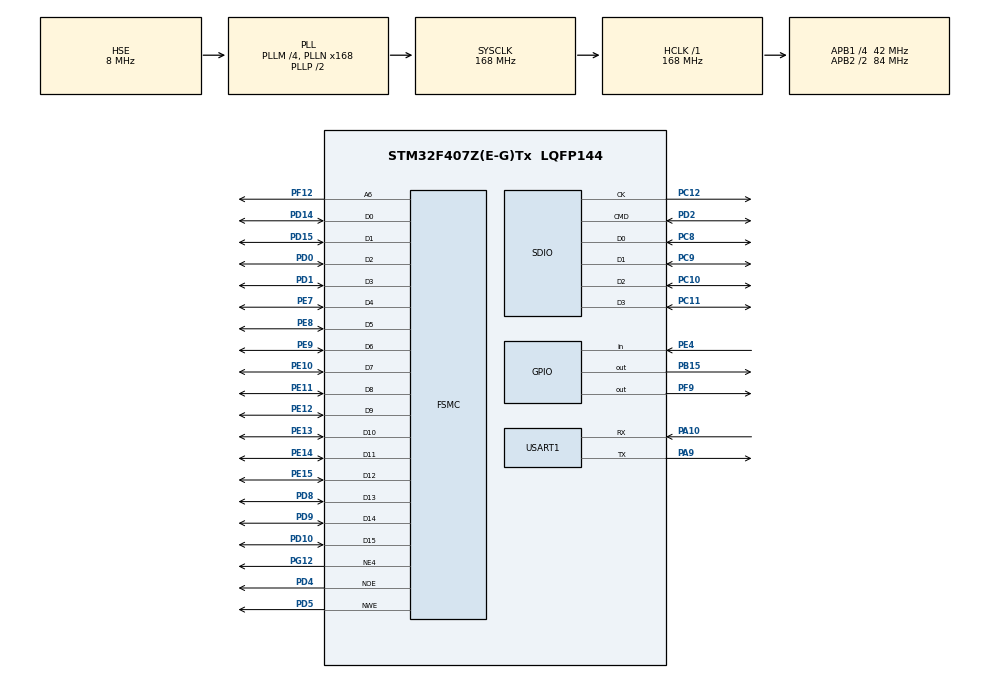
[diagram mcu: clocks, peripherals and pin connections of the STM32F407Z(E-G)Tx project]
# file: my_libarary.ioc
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Dma.Request0=USART1_RX
Dma.Request1=USART1_TX
Dma.Request2=SDIO
Dma.SDIO.2.Direction=DMA_PERIPH_TO_MEMORY
Dma.SDIO.2.FIFOMode=DMA_FIFOMODE_ENABLE
Dma.SDIO.2.FIFOThreshold=DMA_FIFO_THRESHOLD_FULL
Dma.SDIO.2.Instance=DMA2_Stream3
Dma.SDIO.2.MemBurst=DMA_MBURST_INC4
Dma.SDIO.2.MemDataAlignment=DMA_MDATAALIGN_WORD
Dma.SDIO.2.MemInc=DMA_MINC_ENABLE
Dma.SDIO.2.Mode=DMA_PFCTRL
Dma.SDIO.2.PeriphBurst=DMA_PBURST_INC4
Dma.SDIO.2.PeriphDataAlignment=DMA_PDATAALIGN_WORD
Dma.SDIO.2.PeriphInc=DMA_PINC_DISABLE
Dma.SDIO.2.Priority=DMA_PRIORITY_LOW
Dma.USART1_RX.0.Direction=DMA_PERIPH_TO_MEMORY
Dma.USART1_RX.0.FIFOMode=DMA_FIFOMODE_DISABLE
Dma.USART1_RX.0.Instance=DMA2_Stream2
Dma.USART1_RX.0.MemDataAlignment=DMA_MDATAALIGN_BYTE
Dma.USART1_RX.0.MemInc=DMA_MINC_ENABLE
Dma.USART1_RX.0.Mode=DMA_CIRCULAR
Dma.USART1_RX.0.PeriphDataAlignment=DMA_PDATAALIGN_BYTE
Dma.USART1_RX.0.PeriphInc=DMA_PINC_DISABLE
Dma.USART1_RX.0.Priority=DMA_PRIORITY_LOW
Dma.USART1_TX.1.Direction=DMA_MEMORY_TO_PERIPH
Dma.USART1_TX.1.FIFOMode=DMA_FIFOMODE_DISABLE
Dma.USART1_TX.1.Instance=DMA2_Stream7
Dma.USART1_TX.1.MemDataAlignment=DMA_MDATAALIGN_BYTE
Dma.USART1_TX.1.MemInc=DMA_MINC_ENABLE
Dma.USART1_TX.1.Mode=DMA_NORMAL
Dma.USART1_TX.1.PeriphDataAlignment=DMA_PDATAALIGN_BYTE
Dma.USART1_TX.1.PeriphInc=DMA_PINC_DISABLE
Dma.USART1_TX.1.Priority=DMA_PRIORITY_LOW
FATFS.BSP.number=1
FATFS.USE_DMA_CODE_SD=1
FATFS._CODE_PAGE=936
FATFS._USE_LFN=3
FATFS0.BSP.STBoard=false
FATFS0.BSP.api=Unknown
FATFS0.BSP.instance=PE4
FATFS0.BSP.ip=GPIO
FATFS0.BSP.mode=Input
FATFS0.BSP.name=Detect_SDIO
FATFS0.BSP.solution=PE4
Mcu.Family=STM32F4
Mcu.Name=STM32F407Z(E-G)Tx
Mcu.Package=LQFP144
NVIC.DMA2_Stream2_IRQn=true\:0\:0\:false\:false\:true\:false\:true\:true
NVIC.DMA2_Stream3_IRQn=true\:0\:0\:false\:false\:true\:false\:true\:true
NVIC.DMA2_Stream7_IRQn=true\:0\:0\:false\:false\:true\:false\:true\:true
NVIC.PriorityGroup=NVIC_PRIORITYGROUP_4
NVIC.SDIO_IRQn=true\:0\:0\:false\:false\:true\:true\:true\:true
NVIC.TIM6_DAC_IRQn=true\:0\:0\:false\:false\:true\:true\:true\:true
NVIC.TIM7_IRQn=true\:0\:0\:false\:false\:true\:true\:true\:true
NVIC.USART1_IRQn=true\:0\:0\:false\:false\:true\:true\:true\:true
PA10.Mode=Asynchronous
PA10.Signal=USART1_RX
PA13.Mode=Serial_Wire
PA13.Signal=SYS_JTMS-SWDIO
PA14.Mode=Serial_Wire
PA14.Signal=SYS_JTCK-SWCLK
PA9.Mode=Asynchronous
PA9.Signal=USART1_TX
PB15.Signal=GPIO_Output
PB3.Signal=SPI1_SCK
PB4.Signal=SPI1_MISO
PB5.Signal=SPI1_MOSI
PC10.Mode=SD_4_bits_Wide_bus
PC10.Signal=SDIO_D2
PC11.Mode=SD_4_bits_Wide_bus
PC11.Signal=SDIO_D3
PC12.Mode=SD_4_bits_Wide_bus
PC12.Signal=SDIO_CK
PC14-OSC32_IN.Mode=LSE-External-Oscillator
PC14-OSC32_IN.Signal=RCC_OSC32_IN
PC15-OSC32_OUT.Mode=LSE-External-Oscillator
PC15-OSC32_OUT.Signal=RCC_OSC32_OUT
PC8.Mode=SD_4_bits_Wide_bus
PC8.Signal=SDIO_D0
PC9.Mode=SD_4_bits_Wide_bus
PC9.Signal=SDIO_D1
PD0.Signal=FSMC_D2_DA2
PD1.Signal=FSMC_D3_DA3
PD10.Signal=FSMC_D15_DA15
PD14.Signal=FSMC_D0_DA0
PD15.Signal=FSMC_D1_DA1
PD2.Mode=SD_4_bits_Wide_bus
PD2.Signal=SDIO_CMD
PD4.Signal=FSMC_NOE
PD5.Signal=FSMC_NWE
PD8.Signal=FSMC_D13_DA13
PD9.Signal=FSMC_D14_DA14
PE10.Signal=FSMC_D7_DA7
PE11.Signal=FSMC_D8_DA8
PE12.Signal=FSMC_D9_DA9
PE13.Signal=FSMC_D10_DA10
PE14.Signal=FSMC_D11_DA11
PE15.Signal=FSMC_D12_DA12
PE4.Signal=GPIO_Input
PE7.Signal=FSMC_D4_DA4
PE8.Signal=FSMC_D5_DA5
PE9.Signal=FSMC_D6_DA6
PF12.Signal=FSMC_A6
PF9.Signal=GPIO_Output
PG12.Mode=NorPsramChipSelect4_1
PG12.Signal=FSMC_NE4
PH0-OSC_IN.Mode=HSE-External-Oscillator
PH0-OSC_IN.Signal=RCC_OSC_IN
PH1-OSC_OUT.Mode=HSE-External-Oscillator
PH1-OSC_OUT.Signal=RCC_OSC_OUT
ProjectManager.HeapSize=0x2000
ProjectManager.StackSize=0x2000
ProjectManager.TargetToolchain=STM32CubeIDE
RCC.48MHZClocksFreq_Value=48000000
RCC.AHBFreq_Value=168000000
RCC.APB1CLKDivider=RCC_HCLK_DIV4
RCC.APB1Freq_Value=42000000
RCC.APB1TimFreq_Value=84000000
RCC.APB2CLKDivider=RCC_HCLK_DIV2
RCC.APB2Freq_Value=84000000
RCC.APB2TimFreq_Value=168000000
RCC.CortexFreq_Value=168000000
RCC.HCLKFreq_Value=168000000
RCC.HSE_VALUE=8000000
RCC.HSI_VALUE=16000000
RCC.PLLM=4
RCC.PLLN=168
RCC.PLLQ=7
RCC.PLLSourceVirtual=RCC_PLLSOURCE_HSE
RCC.SYSCLKFreq_VALUE=168000000
RCC.SYSCLKSource=RCC_SYSCLKSOURCE_PLLCLK
RCC.VCOOutputFreq_Value=336000000
SH.FSMC_A6.0=FSMC_A6,A6_1
SH.FSMC_D0_DA0.0=FSMC_D0,16b-d1
SH.FSMC_D10_DA10.0=FSMC_D10,16b-d1
SH.FSMC_D11_DA11.0=FSMC_D11,16b-d1
SH.FSMC_D12_DA12.0=FSMC_D12,16b-d1
SH.FSMC_D13_DA13.0=FSMC_D13,16b-d1
SH.FSMC_D14_DA14.0=FSMC_D14,16b-d1
SH.FSMC_D15_DA15.0=FSMC_D15,16b-d1
SH.FSMC_D1_DA1.0=FSMC_D1,16b-d1
SH.FSMC_D2_DA2.0=FSMC_D2,16b-d1
SH.FSMC_D3_DA3.0=FSMC_D3,16b-d1
SH.FSMC_D4_DA4.0=FSMC_D4,16b-d1
SH.FSMC_D5_DA5.0=FSMC_D5,16b-d1
SH.FSMC_D6_DA6.0=FSMC_D6,16b-d1
SH.FSMC_D7_DA7.0=FSMC_D7,16b-d1
SH.FSMC_D8_DA8.0=FSMC_D8,16b-d1
SH.FSMC_D9_DA9.0=FSMC_D9,16b-d1
SH.FSMC_NOE.0=FSMC_NOE,Lcd1
SH.FSMC_NWE.0=FSMC_NWE,Lcd1
TIM6.Prescaler=84-1
TIM7.AutoReloadPreload=TIM_AUTORELOAD_PRELOAD_ENABLE
TIM7.Period=8400-1
TIM7.Prescaler=10-1
TIM7.TIM_MasterOutputTrigger=TIM_TRGO_UPDATE
USART1.VirtualMode=VM_ASYNC
VP_CRC_VS_CRC.Mode=CRC_Activate
VP_FATFS_VS_SDIO.Mode=SDIO
VP_TIM6_VS_ClockSourceINT.Mode=Enable_Timer
VP_TIM7_VS_ClockSourceINT.Mode=Enable_Timer
board=custom

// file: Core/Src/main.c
/* USER CODE BEGIN Header */
/**
  ******************************************************************************
  * @file           : main.c
  * @brief          : Main program body
  ******************************************************************************
  * @attention
  *
  * Copyright (c) 2023 STMicroelectronics.
  * All rights reserved.
  *
  * This software is licensed under terms that can be found in the LICENSE file
  * in the root directory of this software component.
  * If no LICENSE file comes with this software, it is provided AS-IS.
  *
  ******************************************************************************
  */
/* USER CODE END Header */
#include "main.h"
#include "crc.h"
#include "dma.h"
#include "fatfs.h"
#include "sdio.h"
#include "tim.h"
#include "usart.h"
#include "gpio.h"
#include "fsmc.h"

/* USER CODE BEGIN Includes */
#include "ConnectCplusplus.h"
#include "lvgl.h"
/* USER CODE END Includes */

void SystemClock_Config(void);

int main(void)
{

  /* MCU Configuration--------------------------------------------------------*/

  /* Reset of all peripherals, Initializes the Flash interface and the Systick. */
  HAL_Init();

  /* Configure the system clock */
  SystemClock_Config();

  /* Initialize all configured peripherals */
  MX_GPIO_Init();
  MX_DMA_Init();
  MX_USART1_UART_Init();
  MX_TIM6_Init();
  MX_FSMC_Init();
  MX_TIM7_Init();
  MX_CRC_Init();
  MX_SDIO_SD_Init();
  MX_FATFS_Init();
  /* USER CODE BEGIN 2 */
    HAL_TIM_Base_Start_IT(&htim7);
    //Step();
    MyMain();
  /* USER CODE END 2 */

  /* Infinite loop */
  while (1)
  {

  }
}

void SystemClock_Config(void)
{
  RCC_OscInitTypeDef RCC_OscInitStruct = {0};
  RCC_ClkInitTypeDef RCC_ClkInitStruct = {0};

  /** Configure the main internal regulator output voltage
  */
  __HAL_RCC_PWR_CLK_ENABLE();
  __HAL_PWR_VOLTAGESCALING_CONFIG(PWR_REGULATOR_VOLTAGE_SCALE1);

  /** Initializes the RCC Oscillators according to the specified parameters
  * in the RCC_OscInitTypeDef structure.
  */
  RCC_OscInitStruct.OscillatorType = RCC_OSCILLATORTYPE_HSE;
  RCC_OscInitStruct.HSEState = RCC_HSE_ON;
  RCC_OscInitStruct.PLL.PLLState = RCC_PLL_ON;
  RCC_OscInitStruct.PLL.PLLSource = RCC_PLLSOURCE_HSE;
  RCC_OscInitStruct.PLL.PLLM = 4;
  RCC_OscInitStruct.PLL.PLLN = 168;
  RCC_OscInitStruct.PLL.PLLP = RCC_PLLP_DIV2;
  RCC_OscInitStruct.PLL.PLLQ = 7;
  if (HAL_RCC_OscConfig(&RCC_OscInitStruct) != HAL_OK)
  {
    Error_Handler();
  }

  /** Initializes the CPU, AHB and APB buses clocks
  */
  RCC_ClkInitStruct.ClockType = RCC_CLOCKTYPE_HCLK|RCC_CLOCKTYPE_SYSCLK
                              |RCC_CLOCKTYPE_PCLK1|RCC_CLOCKTYPE_PCLK2;
  RCC_ClkInitStruct.SYSCLKSource = RCC_SYSCLKSOURCE_PLLCLK;
  RCC_ClkInitStruct.AHBCLKDivider = RCC_SYSCLK_DIV1;
  RCC_ClkInitStruct.APB1CLKDivider = RCC_HCLK_DIV4;
  RCC_ClkInitStruct.APB2CLKDivider = RCC_HCLK_DIV2;

  if (HAL_RCC_ClockConfig(&RCC_ClkInitStruct, FLASH_LATENCY_5) != HAL_OK)
  {
    Error_Handler();
  }
}

/* USER CODE BEGIN 4 */
void HAL_TIM_PeriodElapsedCallback(TIM_HandleTypeDef *htim){
    if (htim->Instance==TIM7){
        lv_timer_handler();
    }
}

/* USER CODE END 4 */

void Error_Handler(void)
{
  __disable_irq();
  while (1)
  {
  }
}
